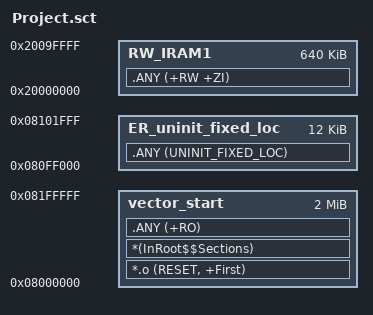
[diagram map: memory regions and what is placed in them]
; *************************************************************
; *** Scatter-Loading Description File generated by uVision ***
; *************************************************************

LR_IROM1 0x08000000 0x00200000  {    ; load region size_region
  vector_start 0x08000000 0x00200000  {  ; load address = execution address
   *.o (RESET, +First)
   *(InRoot$$Sections)
   .ANY (+RO)
  }
  RW_IRAM1 0x20000000 0x000A0000  {  ; RW data
   .ANY (+RW +ZI)
  }
}

LR_uninit_fixed_loc 0x080FF000 0x3000 {
  ER_uninit_fixed_loc 0x080FF000 0x3000 {
    .ANY (UNINIT_FIXED_LOC)
  }
}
